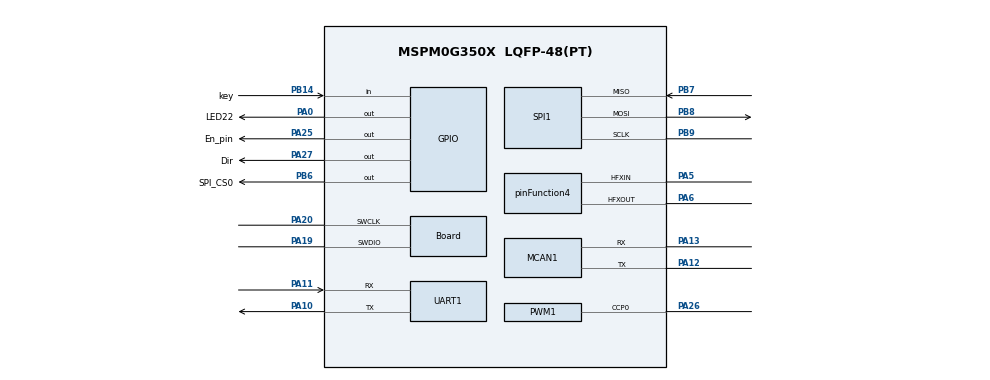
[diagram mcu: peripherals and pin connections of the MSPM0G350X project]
/**
 *
 * @cliArgs --device "MSPM0G350X" --part "Default" --package "LQFP-48(PT)" --product "mspm0_sdk@2.10.00.04"
 * @versions {"tool":"1.28.0+4712"}
 */

/**
 * Import the modules used in this configuration.
 */
const GPIO   = scripting.addModule("/ti/driverlib/GPIO", {}, false);
const GPIO1  = GPIO.addInstance();
const GPIO2  = GPIO.addInstance();
const GPIO3  = GPIO.addInstance();
const GPIO4  = GPIO.addInstance();
const GPIO5  = GPIO.addInstance();
const MCAN   = scripting.addModule("/ti/driverlib/MCAN", {}, false);
const MCAN1  = MCAN.addInstance();
const PWM    = scripting.addModule("/ti/driverlib/PWM", {}, false);
const PWM1   = PWM.addInstance();
const SPI    = scripting.addModule("/ti/driverlib/SPI", {}, false);
const SPI1   = SPI.addInstance();
const SYSCTL = scripting.addModule("/ti/driverlib/SYSCTL");
const TIMER  = scripting.addModule("/ti/driverlib/TIMER", {}, false);
const TIMER1 = TIMER.addInstance();
const UART   = scripting.addModule("/ti/driverlib/UART", {}, false);
const UART1  = UART.addInstance();

/**
 * Write custom configuration values to the imported modules.
 */
const divider6       = system.clockTree["PLL_CLK2X_DIV"];
divider6.divideValue = 4;

const divider9       = system.clockTree["UDIV"];
divider9.divideValue = 2;

const multiplier2         = system.clockTree["PLL_QDIV"];
multiplier2.multiplyValue = 4;

const mux2       = system.clockTree["CANCLKMUX"];
mux2.inputSelect = "CANCLKMUX_PLLCLK1_OUT";

const mux4       = system.clockTree["EXHFMUX"];
mux4.inputSelect = "EXHFMUX_XTAL";

const mux8       = system.clockTree["HSCLKMUX"];
mux8.inputSelect = "HSCLKMUX_SYSPLL0";

const mux12       = system.clockTree["SYSPLLMUX"];
mux12.inputSelect = "zSYSPLLMUX_HFCLK";

const pinFunction4                        = system.clockTree["HFXT"];
pinFunction4.enable                       = true;
pinFunction4.inputFreq                    = 40;
pinFunction4.HFCLKMonitor                 = true;
pinFunction4.HFXTStartup                  = 10;
pinFunction4.peripheral.$assign           = "SYSCTL";
pinFunction4.peripheral.hfxInPin.$assign  = "PA5";
pinFunction4.peripheral.hfxOutPin.$assign = "PA6";

GPIO1.$name                         = "LED";
GPIO1.associatedPins[0].$name       = "LED22";
GPIO1.associatedPins[0].pin.$assign = "PA0";

const Board                       = scripting.addModule("/ti/driverlib/Board", {}, false);
Board.peripheral.$assign          = "DEBUGSS";
Board.peripheral.swclkPin.$assign = "PA20";
Board.peripheral.swdioPin.$assign = "PA19";

GPIO2.$name                          = "SPI_CS";
GPIO2.associatedPins[0].$name        = "SPI_CS0";
GPIO2.associatedPins[0].assignedPort = "PORTB";
GPIO2.associatedPins[0].initialValue = "SET";
GPIO2.associatedPins[0].pin.$assign  = "PB6";

GPIO3.$name                         = "STP_pins";
GPIO3.associatedPins[0].$name       = "Dir";
GPIO3.associatedPins[0].pin.$assign = "PA27";

GPIO4.$name                         = "EN";
GPIO4.associatedPins[0].$name       = "En_pin";
GPIO4.associatedPins[0].pin.$assign = "PA25";

GPIO5.$name                         = "KEY";
GPIO5.associatedPins[0].$name       = "key";
GPIO5.associatedPins[0].direction   = "INPUT";
GPIO5.associatedPins[0].pin.$assign = "PB14";

MCAN1.$name                    = "MCAN0";
MCAN1.enableInterrupt          = true;
MCAN1.loopbackMode             = "internal";
MCAN1.fdMode                   = false;
MCAN1.spPercent                = 80;
MCAN1.desiredNomRate           = 1000;
MCAN1.stdFiltElem              = "001";
MCAN1.stdFiltType              = "00";
MCAN1.stdFiltID2               = 2047;
MCAN1.extFiltElem              = "001";
MCAN1.txBufElemSize            = "DL_MCAN_ELEM_SIZE_8BYTES";
MCAN1.txBufNum                 = 1;
MCAN1.rxBufElemSize            = "DL_MCAN_ELEM_SIZE_8BYTES";
MCAN1.rxFIFO0ElemSize          = "DL_MCAN_ELEM_SIZE_8BYTES";
MCAN1.rxFIFO1ElemSize          = "DL_MCAN_ELEM_SIZE_8BYTES";
MCAN1.rxFIFO0startAddr         = 180;
MCAN1.rxFIFO0size              = 4;
MCAN1.rxFIFO0waterMark         = 1;
MCAN1.rxFIFO1startAddr         = 252;
MCAN1.rxBufStartAddr           = 284;
MCAN1.interruptLine            = ["DL_MCAN_INTR_LINE_NUM_0"];
MCAN1.m0interrupts             = ["DL_MCAN_MSP_INTERRUPT_LINE0"];
MCAN1.interruptFlags           = ["DL_MCAN_INTERRUPT_RF0N","DL_MCAN_INTERRUPT_TEFN"];
MCAN1.interruptLine0Flag       = ["DL_MCAN_INTERRUPT_RF1N","DL_MCAN_INTERRUPT_TEFN"];
MCAN1.peripheral.$assign       = "CANFD0";
MCAN1.peripheral.rxPin.$assign = "PA13";
MCAN1.peripheral.txPin.$assign = "PA12";
MCAN1.txPinConfig.$name        = "ti_driverlib_gpio_GPIOPinGeneric5";
MCAN1.rxPinConfig.$name        = "ti_driverlib_gpio_GPIOPinGeneric10";

PWM1.$name                              = "PWM_Step";
PWM1.ccIndex                            = [0];
PWM1.clockPrescale                      = 79;
PWM1.PWM_CHANNEL_0.$name                = "ti_driverlib_pwm_PWMTimerCC0";
PWM1.ccp0PinConfig.direction            = scripting.forceWrite("OUTPUT");
PWM1.ccp0PinConfig.hideOutputInversion  = scripting.forceWrite(false);
PWM1.ccp0PinConfig.onlyInternalResistor = scripting.forceWrite(false);
PWM1.ccp0PinConfig.passedPeripheralType = scripting.forceWrite("Digital");
PWM1.ccp0PinConfig.$name                = "ti_driverlib_gpio_GPIOPinGeneric4";
PWM1.peripheral.$assign                 = "TIMG7";
PWM1.peripheral.ccp0Pin.$assign         = "PA26";

SPI1.$name                              = "SPI_1";
SPI1.polarity                           = "1";
SPI1.phase                              = "1";
SPI1.peripheral.$assign                 = "SPI1";
SPI1.peripheral.sclkPin.$assign         = "PB9";
SPI1.peripheral.mosiPin.$assign         = "PB8";
SPI1.peripheral.misoPin.$assign         = "PB7";
SPI1.sclkPinConfig.direction            = scripting.forceWrite("OUTPUT");
SPI1.sclkPinConfig.onlyInternalResistor = scripting.forceWrite(false);
SPI1.sclkPinConfig.passedPeripheralType = scripting.forceWrite("Digital");
SPI1.sclkPinConfig.$name                = "ti_driverlib_gpio_GPIOPinGeneric2";
SPI1.sclkPinConfig.enableConfig         = true;
SPI1.mosiPinConfig.direction            = scripting.forceWrite("OUTPUT");
SPI1.mosiPinConfig.hideOutputInversion  = scripting.forceWrite(false);
SPI1.mosiPinConfig.onlyInternalResistor = scripting.forceWrite(false);
SPI1.mosiPinConfig.passedPeripheralType = scripting.forceWrite("Digital");
SPI1.mosiPinConfig.$name                = "ti_driverlib_gpio_GPIOPinGeneric3";
SPI1.mosiPinConfig.enableConfig         = true;
SPI1.misoPinConfig.$name                = "ti_driverlib_gpio_GPIOPinGeneric6";
SPI1.misoPinConfig.onlyInternalResistor = scripting.forceWrite(false);
SPI1.misoPinConfig.passedPeripheralType = scripting.forceWrite("Digital");
SPI1.misoPinConfig.enableConfig         = true;
SPI1.cs0PinConfig.$name                 = "ti_driverlib_gpio_GPIOPinGeneric7";
SPI1.cs0PinConfig.direction             = scripting.forceWrite("OUTPUT");
SPI1.cs0PinConfig.hideOutputInversion   = scripting.forceWrite(false);
SPI1.cs0PinConfig.onlyInternalResistor  = scripting.forceWrite(false);
SPI1.cs0PinConfig.passedPeripheralType  = scripting.forceWrite("Digital");

SYSCTL.forceDefaultClkConfig = true;
SYSCTL.clockTreeEn           = true;

TIMER1.$name              = "TIMER_TICK";
TIMER1.timerClkDiv        = 8;
TIMER1.timerClkPrescale   = 10;
TIMER1.timerMode          = "PERIODIC";
TIMER1.timerStartTimer    = true;
TIMER1.interrupts         = ["ZERO"];
TIMER1.interruptPriority  = "3";
TIMER1.timerPeriod        = "1 ms";
TIMER1.peripheral.$assign = "TIMA0";

UART1.$name                            = "UART_DEBUG";
UART1.enabledInterrupts                = ["RX"];
UART1.interruptPriority                = "3";
UART1.targetBaudRate                   = 115200;
UART1.peripheral.$assign               = "UART0";
UART1.peripheral.rxPin.$assign         = "PA11";
UART1.peripheral.txPin.$assign         = "PA10";
UART1.txPinConfig.direction            = scripting.forceWrite("OUTPUT");
UART1.txPinConfig.hideOutputInversion  = scripting.forceWrite(false);
UART1.txPinConfig.onlyInternalResistor = scripting.forceWrite(false);
UART1.txPinConfig.passedPeripheralType = scripting.forceWrite("Digital");
UART1.txPinConfig.$name                = "ti_driverlib_gpio_GPIOPinGeneric0";
UART1.rxPinConfig.hideOutputInversion  = scripting.forceWrite(false);
UART1.rxPinConfig.onlyInternalResistor = scripting.forceWrite(false);
UART1.rxPinConfig.passedPeripheralType = scripting.forceWrite("Digital");
UART1.rxPinConfig.$name                = "ti_driverlib_gpio_GPIOPinGeneric1";

const ProjectConfig              = scripting.addModule("/ti/project_config/ProjectConfig", {}, false);
ProjectConfig.migrationCondition = true;

/**
 * Pinmux solution for unlocked pins/peripherals. This ensures that minor changes to the automatic solver in a future
 * version of the tool will not impact the pinmux you originally saw.  These lines can be completely deleted in order to
 * re-solve from scratch.
 */
SPI1.peripheral.cs0Pin.$suggestSolution = "PA2";
